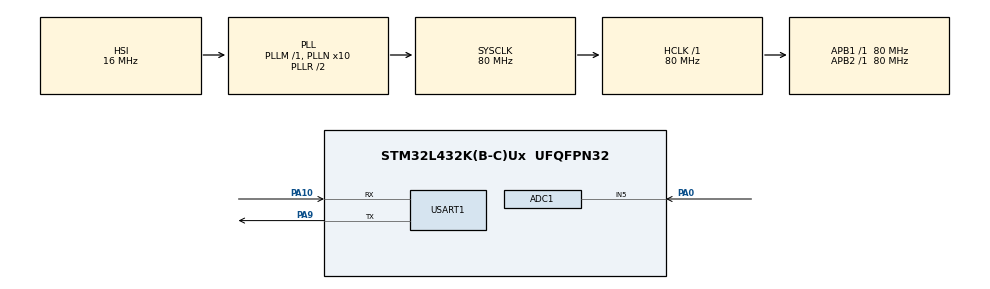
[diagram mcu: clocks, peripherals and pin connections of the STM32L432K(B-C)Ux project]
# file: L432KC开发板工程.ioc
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ADC1.Channel-0\#ChannelRegularConversion=ADC_CHANNEL_5
ADC1.ClockPrescaler=ADC_CLOCK_SYNC_PCLK_DIV4
ADC1.ContinuousConvMode=DISABLE
ADC1.DMAContinuousRequests=ENABLE
ADC1.ExternalTrigConv=ADC_EXTERNALTRIG_T2_TRGO
ADC1.NbrOfConversion=1
ADC1.NbrOfConversionFlag=1
ADC1.OffsetNumber-0\#ChannelRegularConversion=ADC_OFFSET_NONE
ADC1.Rank-0\#ChannelRegularConversion=1
ADC1.SamplingTime-0\#ChannelRegularConversion=ADC_SAMPLETIME_247CYCLES_5
ADC1.master=1
Dma.ADC1.2.Direction=DMA_PERIPH_TO_MEMORY
Dma.ADC1.2.Instance=DMA1_Channel1
Dma.ADC1.2.MemDataAlignment=DMA_MDATAALIGN_HALFWORD
Dma.ADC1.2.MemInc=DMA_MINC_ENABLE
Dma.ADC1.2.Mode=DMA_CIRCULAR
Dma.ADC1.2.PeriphDataAlignment=DMA_PDATAALIGN_HALFWORD
Dma.ADC1.2.PeriphInc=DMA_PINC_DISABLE
Dma.ADC1.2.Priority=DMA_PRIORITY_LOW
Dma.Request0=USART1_RX
Dma.Request1=USART1_TX
Dma.Request2=ADC1
Dma.USART1_RX.0.Direction=DMA_PERIPH_TO_MEMORY
Dma.USART1_RX.0.Instance=DMA1_Channel5
Dma.USART1_RX.0.MemDataAlignment=DMA_MDATAALIGN_BYTE
Dma.USART1_RX.0.MemInc=DMA_MINC_ENABLE
Dma.USART1_RX.0.Mode=DMA_NORMAL
Dma.USART1_RX.0.PeriphDataAlignment=DMA_PDATAALIGN_BYTE
Dma.USART1_RX.0.PeriphInc=DMA_PINC_DISABLE
Dma.USART1_RX.0.Priority=DMA_PRIORITY_LOW
Dma.USART1_TX.1.Direction=DMA_MEMORY_TO_PERIPH
Dma.USART1_TX.1.Instance=DMA1_Channel4
Dma.USART1_TX.1.MemDataAlignment=DMA_MDATAALIGN_BYTE
Dma.USART1_TX.1.MemInc=DMA_MINC_ENABLE
Dma.USART1_TX.1.Mode=DMA_NORMAL
Dma.USART1_TX.1.PeriphDataAlignment=DMA_PDATAALIGN_BYTE
Dma.USART1_TX.1.PeriphInc=DMA_PINC_DISABLE
Dma.USART1_TX.1.Priority=DMA_PRIORITY_LOW
Mcu.Family=STM32L4
Mcu.Name=STM32L432K(B-C)Ux
Mcu.Package=UFQFPN32
NVIC.DMA1_Channel1_IRQn=true\:0\:0\:false\:false\:true\:false\:true\:true
NVIC.DMA1_Channel4_IRQn=true\:0\:0\:false\:false\:true\:false\:true\:true
NVIC.DMA1_Channel5_IRQn=true\:0\:0\:false\:false\:true\:false\:true\:true
NVIC.PriorityGroup=NVIC_PRIORITYGROUP_4
NVIC.USART1_IRQn=true\:0\:0\:false\:false\:true\:false\:true\:true
PA0.Signal=ADCx_IN5
PA10.Mode=Asynchronous
PA10.Signal=USART1_RX
PA13\ (JTMS-SWDIO).Mode=Serial_Wire
PA13\ (JTMS-SWDIO).Signal=SYS_JTMS-SWDIO
PA14\ (JTCK-SWCLK).Mode=Serial_Wire
PA14\ (JTCK-SWCLK).Signal=SYS_JTCK-SWCLK
PA9.Mode=Asynchronous
PA9.Signal=USART1_TX
PC14-OSC32_IN\ (PC14).Mode=LSE-External-Oscillator
PC14-OSC32_IN\ (PC14).Signal=RCC_OSC32_IN
PC15-OSC32_OUT\ (PC15).Mode=LSE-External-Oscillator
PC15-OSC32_OUT\ (PC15).Signal=RCC_OSC32_OUT
ProjectManager.HeapSize=0x200
ProjectManager.StackSize=0x400
ProjectManager.TargetToolchain=MDK-ARM V5.32
RCC.ADCFreq_Value=64000000
RCC.AHBFreq_Value=80000000
RCC.APB1Freq_Value=80000000
RCC.APB1TimFreq_Value=80000000
RCC.APB2Freq_Value=80000000
RCC.APB2TimFreq_Value=80000000
RCC.CortexFreq_Value=80000000
RCC.HCLKFreq_Value=80000000
RCC.HSE_VALUE=8000000
RCC.HSI48_VALUE=48000000
RCC.HSI_VALUE=16000000
RCC.MSI_VALUE=4000000
RCC.PLLN=10
RCC.PLLSourceVirtual=RCC_PLLSOURCE_HSI
RCC.SYSCLKFreq_VALUE=80000000
RCC.SYSCLKSource=RCC_SYSCLKSOURCE_PLLCLK
RCC.USBFreq_Value=64000000
RCC.VCOOutputFreq_Value=160000000
SH.ADCx_IN5.0=ADC1_IN5,IN5-Single-Ended
TIM2.Period=999
TIM2.Prescaler=79
TIM2.TIM_MasterOutputTrigger=TIM_TRGO_UPDATE
USART1.VirtualMode-Asynchronous=VM_ASYNC
VP_TIM2_VS_ClockSourceINT.Mode=Internal
board=custom

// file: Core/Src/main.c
/* USER CODE BEGIN Header */
/**
  ******************************************************************************
  * @file           : main.c
  * @brief          : Main program body
  ******************************************************************************
  * @attention
  *
  * Copyright (c) 2026 STMicroelectronics.
  * All rights reserved.
  *
  * This software is licensed under terms that can be found in the LICENSE file
  * in the root directory of this software component.
  * If no LICENSE file comes with this software, it is provided AS-IS.
  *
  ******************************************************************************
  */
/* USER CODE END Header */
#include "main.h"
#include "adc.h"
#include "dma.h"
#include "tim.h"
#include "usart.h"
#include "gpio.h"
#include "UART_config.h"
#include "Dic_config.h"
#include "stdio.h"

/* USER CODE BEGIN Includes */

/* USER CODE BEGIN PV */

volatile uint16_t adc_raw[2] = {0, 0};    // DMA 写入的原始值 [0]传感器1 [1]传感器2
volatile uint16_t sample_raw[2] = {0, 0}; // 采样完成中断里锁存的本次采样值
volatile uint16_t sample_seq = 0;         // 采样序号 每次采样加1 主控靠它发现丢点
volatile uint8_t adc_ready = 0;           // 新数据标志

/* USER CODE END PV */

/* USER CODE END Includes */

void SystemClock_Config(void);

/* USER CODE BEGIN 0 */

/**
 * @brief 对于主板发送命令的处理函数
 *
 * @param Buffer
 * @param Length
 */

void Command_Processing_Callback_Function(uint8_t* Buffer , uint16_t Length){ //UART回调函数

  Command_Processing(Length);

}

/* USER CODE END 0 */

int main(void)
{

  /* MCU Configuration--------------------------------------------------------*/

  /* Reset of all peripherals, Initializes the Flash interface and the Systick. */
  HAL_Init();

  /* Configure the system clock */
  SystemClock_Config();

  /* Initialize all configured peripherals */
  MX_GPIO_Init();
  MX_DMA_Init();
  MX_USART1_UART_Init();
  MX_ADC1_Init();
  MX_TIM2_Init();
  /* USER CODE BEGIN 2 */

#if SCAN_SENSOR_COUNT >= 2
  /*
   * 第二个传感器: 在CubeMX生成的单通道配置基础上 改成两个通道的扫描转换
   * 每次TIM2触发 通道5(PA0 传感器1)和通道6(PA1 传感器2)依次转换 相隔约13微秒
   * DMA把结果依次写进adc_raw[0]和adc_raw[1] 两个都转完后才进一次转换完成中断
   * 写在这里而不是改CubeMX 是为了重新生成代码时不被覆盖
   */
  {
    GPIO_InitTypeDef GPIO_InitStruct = {0};
    ADC_ChannelConfTypeDef sConfig = {0};

    /* PA1设为模拟输入 */
    __HAL_RCC_GPIOA_CLK_ENABLE();
    GPIO_InitStruct.Pin = GPIO_PIN_1;
    GPIO_InitStruct.Mode = GPIO_MODE_ANALOG_ADC_CONTROL;
    GPIO_InitStruct.Pull = GPIO_NOPULL;
    HAL_GPIO_Init(GPIOA, &GPIO_InitStruct);

    /* 转换个数改为2 开启扫描 其余参数沿用CubeMX的配置 */
    hadc1.Init.ScanConvMode = ADC_SCAN_ENABLE;
    hadc1.Init.NbrOfConversion = 2;
    hadc1.Init.EOCSelection = ADC_EOC_SEQ_CONV;

    if (HAL_ADC_Init(&hadc1) != HAL_OK)
    {
      Error_Handler();
    }

    /* 第2个转换: 通道6 采样时间与通道5相同 */
    sConfig.Channel = ADC_CHANNEL_6;
    sConfig.Rank = ADC_REGULAR_RANK_2;
    sConfig.SamplingTime = ADC_SAMPLETIME_247CYCLES_5;
    sConfig.SingleDiff = ADC_SINGLE_ENDED;
    sConfig.OffsetNumber = ADC_OFFSET_NONE;
    sConfig.Offset = 0;

    if (HAL_ADC_ConfigChannel(&hadc1, &sConfig) != HAL_OK)
    {
      Error_Handler();
    }
  }
#endif

  /* 上电后执行一次；此时 TIM2 尚未启动 */

  if (HAL_ADCEx_Calibration_Start(&hadc1, ADC_SINGLE_ENDED) != HAL_OK)
  {

    Error_Handler();

  }

  if (HAL_ADC_Start_DMA(&hadc1,(uint32_t *)adc_raw, SCAN_SENSOR_COUNT) != HAL_OK)
  {

    Error_Handler();

  }

  /*

  开始以 1000 Hz 采样 : HAL_TIM_Base_Start(&htim2);
  停止产生采样触发 : HAL_TIM_Base_Stop(&htim2);
  读取最新 ADC 原始值 : uint16_t raw = adc_raw[0];

   */

  /* TIM2计数频率为1MHz 按SCAN_SAMPLE_RATE_HZ设定采样率 覆盖CubeMX里填的周期 */
  __HAL_TIM_SET_AUTORELOAD(&htim2, 1000000U / SCAN_SAMPLE_RATE_HZ - 1U);

  UART_Init(&huart1, Command_Processing_Callback_Function, COMMAND_MAX_SIZE); //UART接收初始化 定义数据处理函数

  /* USER CODE END 2 */

  /* Infinite loop */
  while (1)
  {

    /* USER CODE BEGIN 3 */

    /*
     * 每个采样发一帧 7字节 带采样序号和两个传感器的ADC原始值 帧格式见UART_config.h
     * 换算成距离放到主控做
     * 7字节发完约0.61ms 赶得上1ms一次的采样
     * 如果上一帧还没发完 这个采样留到下一圈循环 来不及就被新采样覆盖 主控从序号跳变能看出来
     */
    if (ifsend && adc_ready && huart1.gState == HAL_UART_STATE_READY)
    {
      static uint8_t tx_frame[SCAN_FRAME_LENGTH];
      uint16_t raw1;
      uint16_t raw2;
      uint16_t seq;
      uint8_t crc = 0xFF;
      uint8_t i;
      uint8_t bit;

      /* 序号和采样值要成套取出 中间不能被采样中断打断 */
      __disable_irq();
      raw1 = sample_raw[0];
      raw2 = sample_raw[1];
      seq = sample_seq;
      adc_ready = 0;
      __enable_irq();

      tx_frame[0] = SCAN_FRAME_HEADER;
      tx_frame[1] = (uint8_t)(seq & 0xFF);
      tx_frame[2] = (uint8_t)(seq >> 8);

      /* 两个12位采样挤成3字节 */
      tx_frame[3] = (uint8_t)(raw1 & 0xFF);
      tx_frame[4] = (uint8_t)(((raw1 >> 8) & 0x0F) | ((raw2 & 0x0F) << 4));
      tx_frame[5] = (uint8_t)(raw2 >> 4);

      /* CRC8 多项式0x07 初值0xFF */
      for (i = 0; i < SCAN_FRAME_LENGTH - 1; i++)
      {
        crc ^= tx_frame[i];

        for (bit = 0; bit < 8; bit++)
        {
          crc = (crc & 0x80) ? (uint8_t)((crc << 1) ^ 0x07) : (uint8_t)(crc << 1);
        }
      }

      tx_frame[SCAN_FRAME_LENGTH - 1] = crc;

      UART_Send_Data(&huart1, tx_frame, SCAN_FRAME_LENGTH);
    }
  }
  /* USER CODE END 3 */
}

void SystemClock_Config(void)
{
  RCC_OscInitTypeDef RCC_OscInitStruct = {0};
  RCC_ClkInitTypeDef RCC_ClkInitStruct = {0};

  /** Configure the main internal regulator output voltage
  */
  if (HAL_PWREx_ControlVoltageScaling(PWR_REGULATOR_VOLTAGE_SCALE1) != HAL_OK)
  {
    Error_Handler();
  }

  /** Initializes the RCC Oscillators according to the specified parameters
  * in the RCC_OscInitTypeDef structure.
  */
  RCC_OscInitStruct.OscillatorType = RCC_OSCILLATORTYPE_HSI;
  RCC_OscInitStruct.HSIState = RCC_HSI_ON;
  RCC_OscInitStruct.HSICalibrationValue = RCC_HSICALIBRATION_DEFAULT;
  RCC_OscInitStruct.PLL.PLLState = RCC_PLL_ON;
  RCC_OscInitStruct.PLL.PLLSource = RCC_PLLSOURCE_HSI;
  RCC_OscInitStruct.PLL.PLLM = 1;
  RCC_OscInitStruct.PLL.PLLN = 10;
  RCC_OscInitStruct.PLL.PLLP = RCC_PLLP_DIV7;
  RCC_OscInitStruct.PLL.PLLQ = RCC_PLLQ_DIV2;
  RCC_OscInitStruct.PLL.PLLR = RCC_PLLR_DIV2;
  if (HAL_RCC_OscConfig(&RCC_OscInitStruct) != HAL_OK)
  {
    Error_Handler();
  }

  /** Initializes the CPU, AHB and APB buses clocks
  */
  RCC_ClkInitStruct.ClockType = RCC_CLOCKTYPE_HCLK|RCC_CLOCKTYPE_SYSCLK
                              |RCC_CLOCKTYPE_PCLK1|RCC_CLOCKTYPE_PCLK2;
  RCC_ClkInitStruct.SYSCLKSource = RCC_SYSCLKSOURCE_PLLCLK;
  RCC_ClkInitStruct.AHBCLKDivider = RCC_SYSCLK_DIV1;
  RCC_ClkInitStruct.APB1CLKDivider = RCC_HCLK_DIV1;
  RCC_ClkInitStruct.APB2CLKDivider = RCC_HCLK_DIV1;

  if (HAL_RCC_ClockConfig(&RCC_ClkInitStruct, FLASH_LATENCY_4) != HAL_OK)
  {
    Error_Handler();
  }
}

/* USER CODE BEGIN 4 */

void HAL_ADC_ConvCpltCallback(ADC_HandleTypeDef *hadc)
{
    if (hadc->Instance == ADC1)
    {
        //立刻锁存 下一次采样会覆盖adc_raw
        sample_raw[0] = (uint16_t)(adc_raw[0] & 0x0FFF);
#if SCAN_SENSOR_COUNT >= 2
        sample_raw[1] = (uint16_t)(adc_raw[1] & 0x0FFF);
#else
        sample_raw[1] = SCAN_RAW_NOT_INSTALLED; //没装第二个传感器
#endif
        sample_seq++;
        adc_ready = 1;
    }
}

/* USER CODE END 4 */

void Error_Handler(void)
{
  __disable_irq();
  while (1)
  {
  }
}
